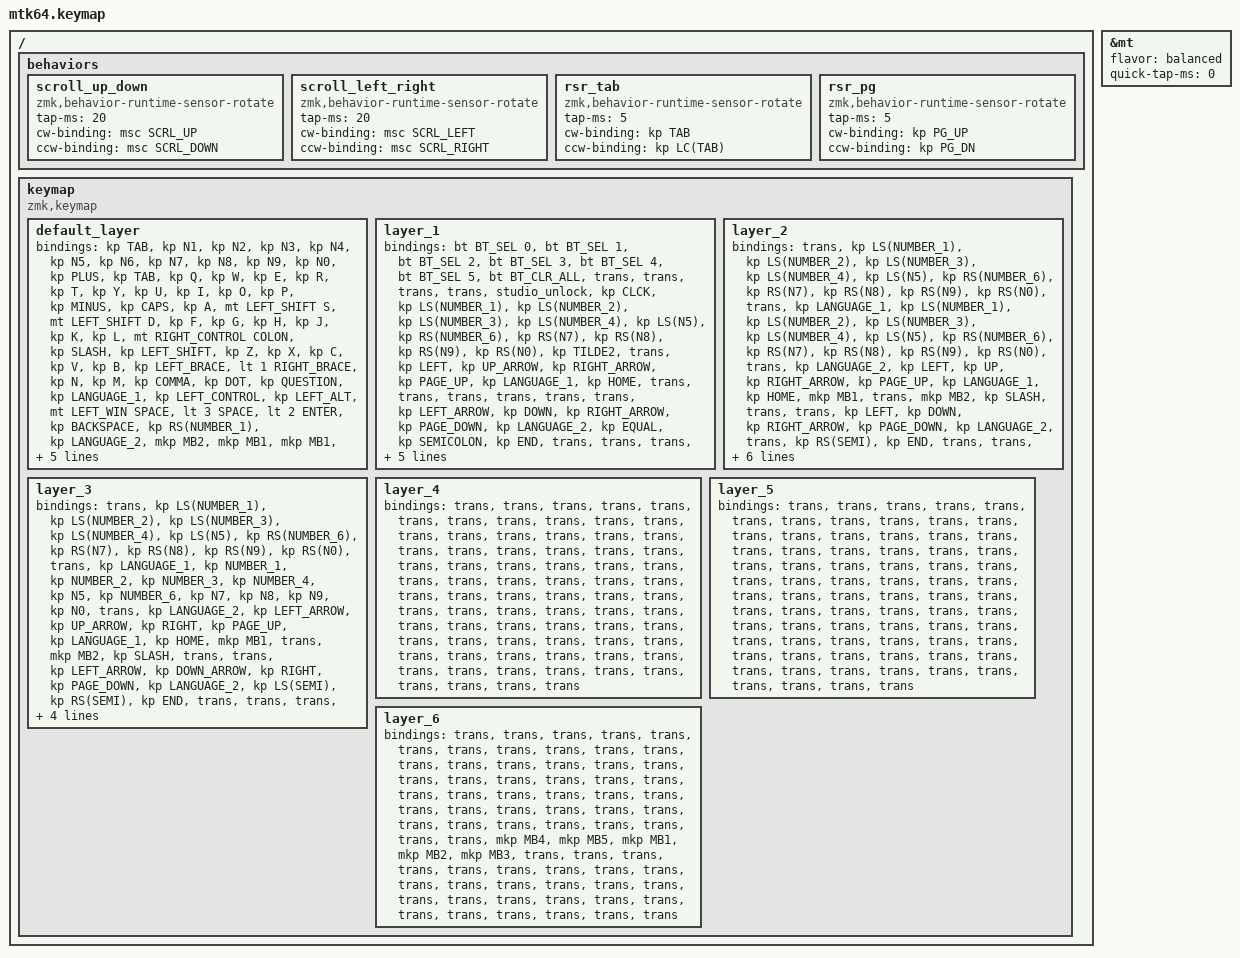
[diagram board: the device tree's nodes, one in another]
#include <behaviors.dtsi>
#include <dt-bindings/zmk/bt.h>
#include <dt-bindings/zmk/keys.h>
#include <dt-bindings/zmk/pointing.h>
#include "keycode_japanese.h"
#include <behaviors/runtime-sensor-rotate.dtsi>

// スクロール量の設定

#define ZMK_POINTING_DEFAULT_SCRL_VAL 100

&mt {
    flavor = "balanced";
    quick-tap-ms = <0>;
};

/ {
    behaviors {
        // ロータリーエンコーダー（DYA Studioから変更可。以下は初期値）
        scroll_up_down: scroll_up_down {
            compatible = "zmk,behavior-runtime-sensor-rotate";
            #sensor-binding-cells = <0>;
            tap-ms = <20>;
            cw-binding = <&msc SCRL_UP>;
            ccw-binding = <&msc SCRL_DOWN>;
        };

        scroll_left_right: scroll_left_right {
            compatible = "zmk,behavior-runtime-sensor-rotate";
            #sensor-binding-cells = <0>;
            tap-ms = <20>;
            cw-binding = <&msc SCRL_LEFT>;
            ccw-binding = <&msc SCRL_RIGHT>;
        };

        rsr_tab: rsr_tab {
            compatible = "zmk,behavior-runtime-sensor-rotate";
            #sensor-binding-cells = <0>;
            tap-ms = <5>;
            cw-binding = <&kp TAB>;
            ccw-binding = <&kp LC(TAB)>;
        };

        rsr_pg: rsr_pg {
            compatible = "zmk,behavior-runtime-sensor-rotate";
            #sensor-binding-cells = <0>;
            tap-ms = <5>;
            cw-binding = <&kp PG_UP>;
            ccw-binding = <&kp PG_DN>;
        };
    };
};

/ {
    keymap {
        compatible = "zmk,keymap";

        default_layer {
            bindings = <
&kp TAB  &kp N1  &kp N2  &kp N3  &kp N4  &kp N5  &kp N6  &kp N7  &kp N8  &kp N9  &kp N0  &kp PLUS  &kp TAB  &kp Q  &kp W  &kp E  &kp R  &kp T  &kp Y  &kp U  &kp I  &kp O  &kp P  &kp MINUS  &kp CAPS  &kp A  &mt LEFT_SHIFT S  &mt LEFT_SHIFT D  &kp F  &kp G  &kp H  &kp J  &kp K  &kp L  &mt RIGHT_CONTROL COLON  &kp SLASH  &kp LEFT_SHIFT  &kp Z  &kp X  &kp C  &kp V  &kp B  &kp LEFT_BRACE  &lt 1 RIGHT_BRACE  &kp N  &kp M  &kp COMMA  &kp DOT  &kp QUESTION  &kp LANGUAGE_1  &kp LEFT_CONTROL  &kp LEFT_ALT  &mt LEFT_WIN SPACE  &lt 3 SPACE  &lt 2 ENTER  &kp BACKSPACE  &kp RS(NUMBER_1)  &kp LANGUAGE_2  &mkp MB2  &mkp MB1  &mkp MB1  &lt 2 ENTER  &kp ENTER  &tog 1  &lt 3 SPACE  &mkp MB2  &mo 1  &mo 2  &mo 3  &mo 1  &mo 2  &mo 3  &mo 1  &mo 2  &mo 3
            >;

            sensor-bindings = <&scroll_left_right>, <&scroll_up_down>;
        };

        layer_1 {
            bindings = <
&bt BT_SEL 0  &bt BT_SEL 1  &bt BT_SEL 2  &bt BT_SEL 3  &bt BT_SEL 4  &bt BT_SEL 5  &bt BT_CLR_ALL  &trans  &trans  &trans  &trans  &studio_unlock  &kp CLCK  &kp LS(NUMBER_1)  &kp LS(NUMBER_2)  &kp LS(NUMBER_3)  &kp LS(NUMBER_4)  &kp LS(N5)  &kp RS(NUMBER_6)  &kp RS(N7)  &kp RS(N8)  &kp RS(N9)  &kp RS(N0)  &kp TILDE2  &trans  &kp LEFT  &kp UP_ARROW  &kp RIGHT_ARROW  &kp PAGE_UP  &kp LANGUAGE_1  &kp HOME  &trans  &trans  &trans  &trans  &trans  &trans  &kp LEFT_ARROW  &kp DOWN  &kp RIGHT_ARROW  &kp PAGE_DOWN  &kp LANGUAGE_2  &kp EQUAL  &kp SEMICOLON  &kp END  &trans  &trans  &trans  &trans  &trans  &kp ESCAPE  &trans  &trans  &trans  &trans  &trans  &trans  &trans  &trans  &trans  &trans  &trans  &trans  &trans  &trans  &trans  &trans  &trans  &trans  &trans  &trans  &trans  &trans  &trans  &trans
            >;
        };

        layer_2 {
            bindings = <
&trans  &kp LS(NUMBER_1)  &kp LS(NUMBER_2)  &kp LS(NUMBER_3)  &kp LS(NUMBER_4)  &kp LS(N5)  &kp RS(NUMBER_6)  &kp RS(N7)  &kp RS(N8)  &kp RS(N9)  &kp RS(N0)  &trans  &kp LANGUAGE_1  &kp LS(NUMBER_1)  &kp LS(NUMBER_2)  &kp LS(NUMBER_3)  &kp LS(NUMBER_4)  &kp LS(N5)  &kp RS(NUMBER_6)  &kp RS(N7)  &kp RS(N8)  &kp RS(N9)  &kp RS(N0)  &trans  &kp LANGUAGE_2  &kp LEFT  &kp UP  &kp RIGHT_ARROW  &kp PAGE_UP  &kp LANGUAGE_1  &kp HOME  &mkp MB1  &trans  &mkp MB2  &kp SLASH  &trans  &trans  &kp LEFT  &kp DOWN  &kp RIGHT_ARROW  &kp PAGE_DOWN  &kp LANGUAGE_2  &trans  &kp RS(SEMI)  &kp END  &trans  &trans  &trans  &trans  &trans  &trans  &trans  &trans  &trans  &trans  &trans  &trans  &trans  &trans  &trans  &trans  &trans  &trans  &trans  &trans  &trans  &trans  &trans  &trans  &trans  &trans  &trans  &trans  &trans  &trans
            >;

            sensor-bindings = <&rsr_tab>, <&rsr_pg>;
        };

        layer_3 {
            bindings = <
&trans  &kp LS(NUMBER_1)  &kp LS(NUMBER_2)  &kp LS(NUMBER_3)  &kp LS(NUMBER_4)  &kp LS(N5)  &kp RS(NUMBER_6)  &kp RS(N7)  &kp RS(N8)  &kp RS(N9)  &kp RS(N0)  &trans  &kp LANGUAGE_1  &kp NUMBER_1  &kp NUMBER_2  &kp NUMBER_3  &kp NUMBER_4  &kp N5  &kp NUMBER_6  &kp N7  &kp N8  &kp N9  &kp N0  &trans  &kp LANGUAGE_2  &kp LEFT_ARROW  &kp UP_ARROW  &kp RIGHT  &kp PAGE_UP  &kp LANGUAGE_1  &kp HOME  &mkp MB1  &trans  &mkp MB2  &kp SLASH  &trans  &trans  &kp LEFT_ARROW  &kp DOWN_ARROW  &kp RIGHT  &kp PAGE_DOWN  &kp LANGUAGE_2  &kp LS(SEMI)  &kp RS(SEMI)  &kp END  &trans  &trans  &trans  &trans  &trans  &trans  &trans  &trans  &lt 3 SPACE  &trans  &trans  &trans  &trans
            >;

            sensor-bindings = <&scroll_left_right>, <&scroll_up_down>;
        };

        layer_4 {
            bindings = <
&trans  &trans  &trans  &trans  &trans  &trans  &trans  &trans  &trans  &trans  &trans  &trans  &trans  &trans  &trans  &trans  &trans  &trans  &trans  &trans  &trans  &trans  &trans  &trans  &trans  &trans  &trans  &trans  &trans  &trans  &trans  &trans  &trans  &trans  &trans  &trans  &trans  &trans  &trans  &trans  &trans  &trans  &trans  &trans  &trans  &trans  &trans  &trans  &trans  &trans  &trans  &trans  &trans  &trans  &trans  &trans  &trans  &trans  &trans  &trans  &trans  &trans  &trans  &trans  &trans  &trans  &trans  &trans  &trans  &trans  &trans  &trans  &trans  &trans  &trans
            >;
        };

        layer_5 {
            bindings = <
&trans  &trans  &trans  &trans  &trans  &trans  &trans  &trans  &trans  &trans  &trans  &trans  &trans  &trans  &trans  &trans  &trans  &trans  &trans  &trans  &trans  &trans  &trans  &trans  &trans  &trans  &trans  &trans  &trans  &trans  &trans  &trans  &trans  &trans  &trans  &trans  &trans  &trans  &trans  &trans  &trans  &trans  &trans  &trans  &trans  &trans  &trans  &trans  &trans  &trans  &trans  &trans  &trans  &trans  &trans  &trans  &trans  &trans  &trans  &trans  &trans  &trans  &trans  &trans  &trans  &trans  &trans  &trans  &trans  &trans  &trans  &trans  &trans  &trans  &trans
            >;
        };

        layer_6 {
            bindings = <
&trans  &trans  &trans  &trans  &trans  &trans  &trans  &trans  &trans  &trans  &trans  &trans  &trans  &trans  &trans  &trans  &trans  &trans  &trans  &trans  &trans  &trans  &trans  &trans  &trans  &trans  &trans  &trans  &trans  &trans  &trans  &trans  &trans  &trans  &trans  &trans  &trans  &trans  &trans  &trans  &trans  &trans  &trans  &mkp MB4  &mkp MB5  &mkp MB1  &mkp MB2  &mkp MB3  &trans  &trans  &trans  &trans  &trans  &trans  &trans  &trans  &trans  &trans  &trans  &trans  &trans  &trans  &trans  &trans  &trans  &trans  &trans  &trans  &trans  &trans  &trans  &trans  &trans  &trans  &trans
            >;
        };
    };
};
